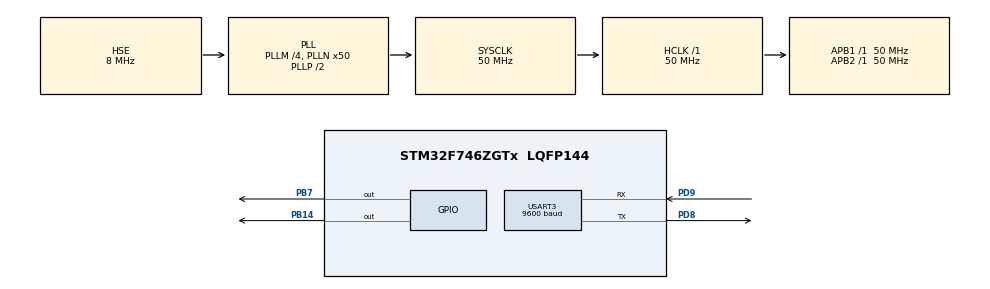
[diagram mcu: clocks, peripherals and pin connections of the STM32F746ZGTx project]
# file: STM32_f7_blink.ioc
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CORTEX_M7.default_mode_Activation=1
FREERTOS.Mutexes01=myMutex01,Dynamic,NULL,Available
FREERTOS.Tasks01=defaultTask,24,128,StartDefaultTask,Default,NULL,Dynamic,NULL,NULL;myTask02,8,128,StartTask02,Default,NULL,Dynamic,NULL,NULL
FREERTOS.configUSE_NEWLIB_REENTRANT=1
Mcu.Family=STM32F7
Mcu.Name=STM32F746ZGTx
Mcu.Package=LQFP144
NVIC.PriorityGroup=NVIC_PRIORITYGROUP_4
PB14.Signal=GPIO_Output
PB7.Signal=GPIO_Output
PD8.Mode=Asynchronous
PD8.Signal=USART3_TX
PD9.Mode=Asynchronous
PD9.Signal=USART3_RX
PH0/OSC_IN.Mode=HSE-External-Oscillator
PH0/OSC_IN.Signal=RCC_OSC_IN
PH1/OSC_OUT.Mode=HSE-External-Oscillator
PH1/OSC_OUT.Signal=RCC_OSC_OUT
ProjectManager.HeapSize=0x200
ProjectManager.StackSize=0x400
ProjectManager.TargetToolchain=STM32CubeIDE
RCC.AHBFreq_Value=50000000
RCC.APB1Freq_Value=50000000
RCC.APB1TimFreq_Value=50000000
RCC.APB2Freq_Value=50000000
RCC.APB2TimFreq_Value=50000000
RCC.CortexFreq_Value=50000000
RCC.HCLKFreq_Value=50000000
RCC.HSE_VALUE=8000000
RCC.HSI_VALUE=16000000
RCC.LSE_VALUE=32768
RCC.PLLM=4
RCC.PLLN=50
RCC.PLLSourceVirtual=RCC_PLLSOURCE_HSE
RCC.SYSCLKFreq_VALUE=50000000
RCC.SYSCLKSource=RCC_SYSCLKSOURCE_PLLCLK
RCC.USBFreq_Value=50000000
RCC.VCOOutputFreq_Value=100000000
USART3.BaudRate=9600
USART3.VirtualMode-Asynchronous=VM_ASYNC
VP_FREERTOS_VS_CMSIS_V2.Mode=CMSIS_V2
board=custom

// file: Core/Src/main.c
/* USER CODE BEGIN Header */
/**
  ******************************************************************************
  * @file           : main.c
  * @brief          : Main program body
  ******************************************************************************
  * @attention
  *
  * Copyright (c) 2025 STMicroelectronics.
  * All rights reserved.
  *
  * This software is licensed under terms that can be found in the LICENSE file
  * in the root directory of this software component.
  * If no LICENSE file comes with this software, it is provided AS-IS.
  *
  ******************************************************************************
  */
/* USER CODE END Header */
#include "main.h"
#include "cmsis_os.h"

UART_HandleTypeDef huart3;

/* Definitions for defaultTask */
osThreadId_t defaultTaskHandle;
const osThreadAttr_t defaultTask_attributes = {
  .name = "defaultTask",
  .stack_size = 128 * 4,
  .priority = (osPriority_t) osPriorityNormal,
};
/* Definitions for myTask02 */
osThreadId_t myTask02Handle;
const osThreadAttr_t myTask02_attributes = {
  .name = "myTask02",
  .stack_size = 128 * 4,
  .priority = (osPriority_t) osPriorityLow,
};
/* Definitions for myMutex01 */
osMutexId_t myMutex01Handle;
const osMutexAttr_t myMutex01_attributes = {
  .name = "myMutex01"
};

void SystemClock_Config(void);
static void MPU_Config(void);
static void MX_GPIO_Init(void);
static void MX_USART3_UART_Init(void);
void StartDefaultTask(void *argument);
void StartTask02(void *argument);

/* USER CODE BEGIN 0 */
char c[]="Task 1: Using shared resource";
char d[]="Task 2: Using shared resource";

/* USER CODE END 0 */

int main(void)
{

  /* MPU Configuration--------------------------------------------------------*/
  MPU_Config();

  /* MCU Configuration--------------------------------------------------------*/

  /* Reset of all peripherals, Initializes the Flash interface and the Systick. */
  HAL_Init();

  /* Configure the system clock */
  SystemClock_Config();

  /* Initialize all configured peripherals */
  MX_GPIO_Init();
  MX_USART3_UART_Init();

  /* Init scheduler */
  osKernelInitialize();
  /* Create the mutex(es) */
  /* creation of myMutex01 */
  myMutex01Handle = osMutexNew(&myMutex01_attributes);

  /* Create the thread(s) */
  /* creation of defaultTask */
  defaultTaskHandle = osThreadNew(StartDefaultTask, NULL, &defaultTask_attributes);

  /* creation of myTask02 */
  myTask02Handle = osThreadNew(StartTask02, NULL, &myTask02_attributes);

  /* Start scheduler */
  osKernelStart();

  /* We should never get here as control is now taken by the scheduler */

  /* Infinite loop */
  while (1)
  {

  }
}

void SystemClock_Config(void)
{
  RCC_OscInitTypeDef RCC_OscInitStruct = {0};
  RCC_ClkInitTypeDef RCC_ClkInitStruct = {0};

  /** Configure the main internal regulator output voltage
  */
  __HAL_RCC_PWR_CLK_ENABLE();
  __HAL_PWR_VOLTAGESCALING_CONFIG(PWR_REGULATOR_VOLTAGE_SCALE3);

  /** Initializes the RCC Oscillators according to the specified parameters
  * in the RCC_OscInitTypeDef structure.
  */
  RCC_OscInitStruct.OscillatorType = RCC_OSCILLATORTYPE_HSE;
  RCC_OscInitStruct.HSEState = RCC_HSE_ON;
  RCC_OscInitStruct.PLL.PLLState = RCC_PLL_ON;
  RCC_OscInitStruct.PLL.PLLSource = RCC_PLLSOURCE_HSE;
  RCC_OscInitStruct.PLL.PLLM = 4;
  RCC_OscInitStruct.PLL.PLLN = 50;
  RCC_OscInitStruct.PLL.PLLP = RCC_PLLP_DIV2;
  RCC_OscInitStruct.PLL.PLLQ = 2;
  if (HAL_RCC_OscConfig(&RCC_OscInitStruct) != HAL_OK)
  {
    Error_Handler();
  }

  /** Activate the Over-Drive mode
  */
  if (HAL_PWREx_EnableOverDrive() != HAL_OK)
  {
    Error_Handler();
  }

  /** Initializes the CPU, AHB and APB buses clocks
  */
  RCC_ClkInitStruct.ClockType = RCC_CLOCKTYPE_HCLK|RCC_CLOCKTYPE_SYSCLK
                              |RCC_CLOCKTYPE_PCLK1|RCC_CLOCKTYPE_PCLK2;
  RCC_ClkInitStruct.SYSCLKSource = RCC_SYSCLKSOURCE_PLLCLK;
  RCC_ClkInitStruct.AHBCLKDivider = RCC_SYSCLK_DIV1;
  RCC_ClkInitStruct.APB1CLKDivider = RCC_HCLK_DIV1;
  RCC_ClkInitStruct.APB2CLKDivider = RCC_HCLK_DIV1;

  if (HAL_RCC_ClockConfig(&RCC_ClkInitStruct, FLASH_LATENCY_1) != HAL_OK)
  {
    Error_Handler();
  }
}

static void MX_USART3_UART_Init(void)
{

  huart3.Instance = USART3;
  huart3.Init.BaudRate = 9600;
  huart3.Init.WordLength = UART_WORDLENGTH_8B;
  huart3.Init.StopBits = UART_STOPBITS_1;
  huart3.Init.Parity = UART_PARITY_NONE;
  huart3.Init.Mode = UART_MODE_TX_RX;
  huart3.Init.HwFlowCtl = UART_HWCONTROL_NONE;
  huart3.Init.OverSampling = UART_OVERSAMPLING_16;
  huart3.Init.OneBitSampling = UART_ONE_BIT_SAMPLE_DISABLE;
  huart3.AdvancedInit.AdvFeatureInit = UART_ADVFEATURE_NO_INIT;
  if (HAL_UART_Init(&huart3) != HAL_OK)
  {
    Error_Handler();
  }

}

static void MX_GPIO_Init(void)
{
  GPIO_InitTypeDef GPIO_InitStruct = {0};

  /* GPIO Ports Clock Enable */
  __HAL_RCC_GPIOH_CLK_ENABLE();
  __HAL_RCC_GPIOB_CLK_ENABLE();
  __HAL_RCC_GPIOD_CLK_ENABLE();

  /*Configure GPIO pin Output Level */
  HAL_GPIO_WritePin(GPIOB, GPIO_PIN_14|GPIO_PIN_7, GPIO_PIN_RESET);

  /*Configure GPIO pins : PB14 PB7 */
  GPIO_InitStruct.Pin = GPIO_PIN_14|GPIO_PIN_7;
  GPIO_InitStruct.Mode = GPIO_MODE_OUTPUT_PP;
  GPIO_InitStruct.Pull = GPIO_NOPULL;
  GPIO_InitStruct.Speed = GPIO_SPEED_FREQ_LOW;
  HAL_GPIO_Init(GPIOB, &GPIO_InitStruct);

}

void StartDefaultTask(void *argument)
{
  /* USER CODE BEGIN 5 */
  /* Infinite loop */
  for(;;)
  {
	  osMutexAcquire(myMutex01Handle, osWaitForever);
	  HAL_UART_Transmit(&huart3, c, sizeof(c), HAL_MAX_DELAY);
	  osMutexRelease(myMutex01Handle);
    osDelay(1000);
  }
  /* USER CODE END 5 */
}

void StartTask02(void *argument)
{
  /* USER CODE BEGIN StartTask02 */
  /* Infinite loop */
  for(;;)
  {
	  osMutexAcquire(myMutex01Handle, osWaitForever);
	  HAL_UART_Transmit(&huart3, d ,sizeof(d),HAL_MAX_DELAY);
	  osMutexRelease(myMutex01Handle);
    osDelay(1000);
  }
  /* USER CODE END StartTask02 */
}

 /* MPU Configuration */

void MPU_Config(void)
{
  MPU_Region_InitTypeDef MPU_InitStruct = {0};

  /* Disables the MPU */
  HAL_MPU_Disable();

  /** Initializes and configures the Region and the memory to be protected
  */
  MPU_InitStruct.Enable = MPU_REGION_ENABLE;
  MPU_InitStruct.Number = MPU_REGION_NUMBER0;
  MPU_InitStruct.BaseAddress = 0x0;
  MPU_InitStruct.Size = MPU_REGION_SIZE_4GB;
  MPU_InitStruct.SubRegionDisable = 0x87;
  MPU_InitStruct.TypeExtField = MPU_TEX_LEVEL0;
  MPU_InitStruct.AccessPermission = MPU_REGION_NO_ACCESS;
  MPU_InitStruct.DisableExec = MPU_INSTRUCTION_ACCESS_DISABLE;
  MPU_InitStruct.IsShareable = MPU_ACCESS_SHAREABLE;
  MPU_InitStruct.IsCacheable = MPU_ACCESS_NOT_CACHEABLE;
  MPU_InitStruct.IsBufferable = MPU_ACCESS_NOT_BUFFERABLE;

  HAL_MPU_ConfigRegion(&MPU_InitStruct);
  /* Enables the MPU */
  HAL_MPU_Enable(MPU_PRIVILEGED_DEFAULT);

}

void Error_Handler(void)
{
  __disable_irq();
  while (1)
  {
  }
}
